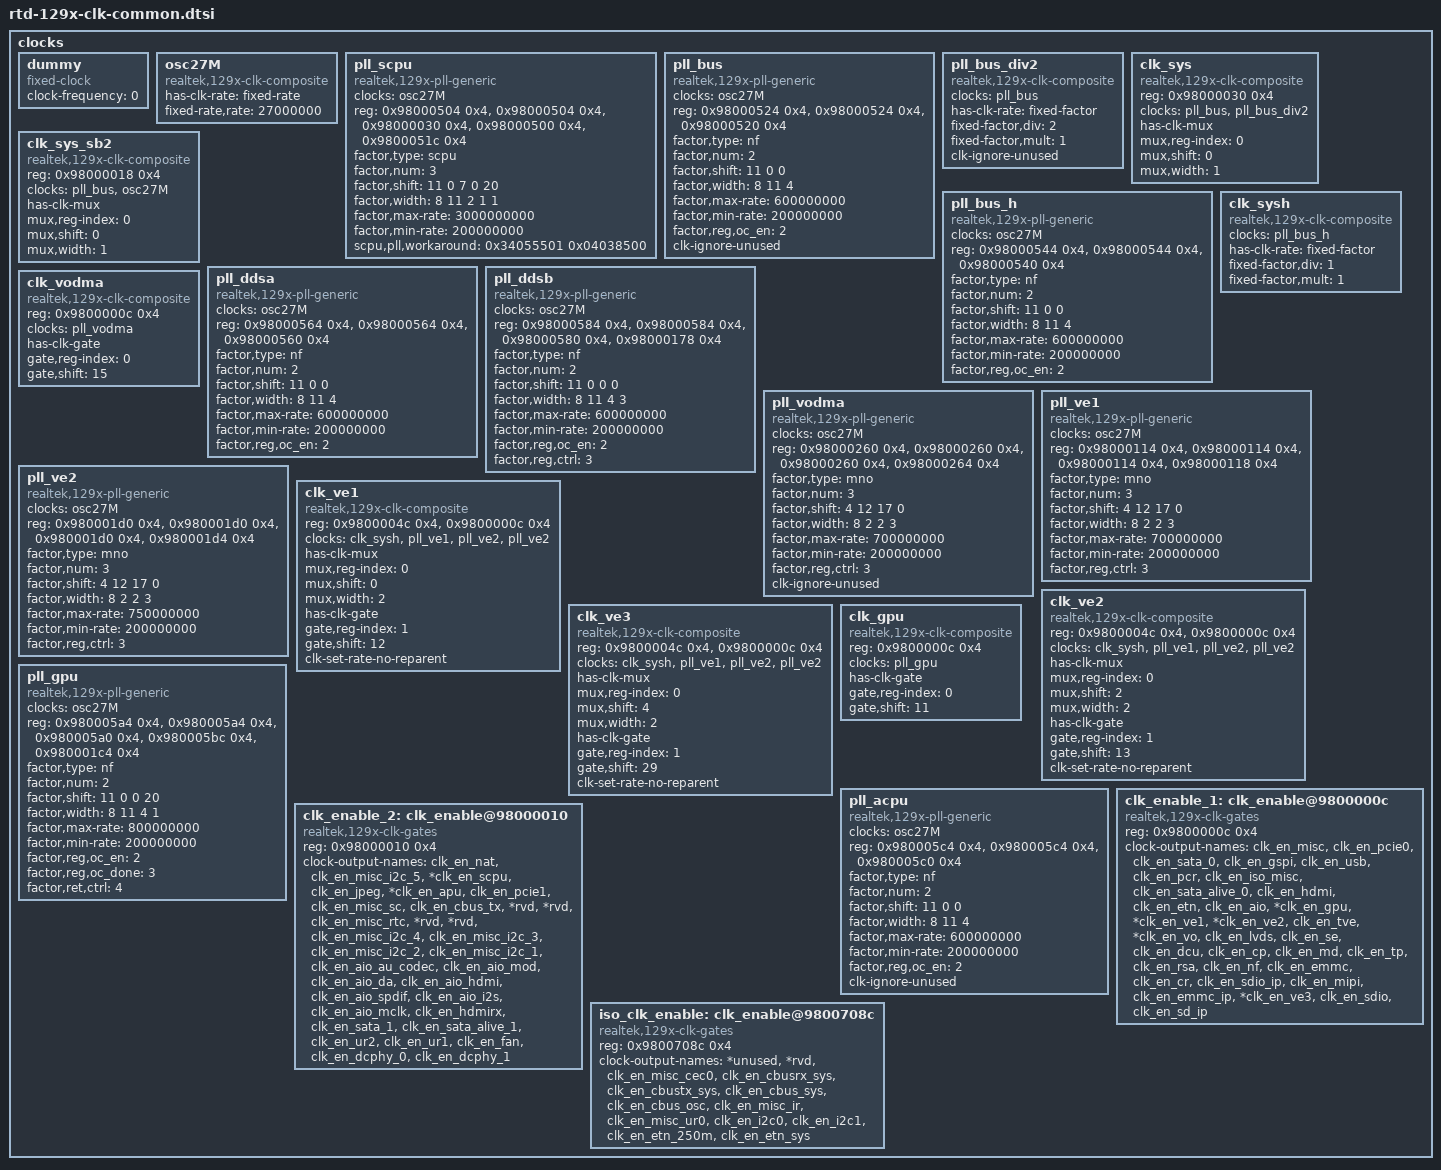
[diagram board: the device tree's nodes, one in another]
/* PLEASE include this file inside a node */
clocks {
    #address-cells = <1>;
    #size-cells = <1>;
    ranges;

    /* This is a dummy clock, to be used as placeholder on
     * other mux clocks when a specific parent clock is not
     * yet implemented. It should be dropped when the driver
     * is complete.
     */
    dummy: dummy {
        compatible = "fixed-clock";
        #clock-cells = <0>;
        clock-frequency = <0>;
    };

    osc27M: osc27M {
        compatible = "realtek,129x-clk-composite";
        #clock-cells = <0>;
        has-clk-rate = "fixed-rate";
        fixed-rate,rate = <27000000>;
    };

    pll_scpu: pll_scpu {
        compatible   = "realtek,129x-pll-generic";
        #clock-cells = <0>;
        clocks       = <&osc27M>;
        reg          = <0x98000504 0x4>,
                       <0x98000504 0x4>,
                       <0x98000030 0x4>,
                       <0x98000500 0x4>, /* oc_en */
                       <0x9800051c 0x4>; /* oc_done */
        factor,type = "scpu";
        factor,num   = <3>;
        factor,shift = <11  0  7  0 20>;
        factor,width = < 8 11  2  1  1>;
        factor,max-rate = <3000000000>;
        factor,min-rate = < 200000000>;            

        scpu,pll,workaround = <
            0x34055501 0x04038500
        >;
    };

    pll_bus: pll_bus {
        compatible   = "realtek,129x-pll-generic";
        #clock-cells = <0>;
        clocks       = <&osc27M>;
        reg          = <0x98000524 0x4>,
                       <0x98000524 0x4>,
                       <0x98000520 0x4>; /* oc_en */
        factor,type  = "nf";
        factor,num   = <2>;
        factor,shift = <11  0 0>;
        factor,width = < 8 11 4>;
        factor,max-rate = <600000000>;
        factor,min-rate = <200000000>;
        factor,reg,oc_en = <2>;

        clk-ignore-unused;
    };

    pll_bus_div2: pll_bus_div2 {
        compatible   = "realtek,129x-clk-composite";
        #clock-cells = <0>;
        clocks       = <&pll_bus>;

        has-clk-rate = "fixed-factor";
        fixed-factor,div  = <2>;
        fixed-factor,mult = <1>;

        clk-ignore-unused;
    };

    clk_sys: clk_sys {
        compatible   = "realtek,129x-clk-composite";
        #clock-cells = <0>;
        reg          = <0x98000030 0x4>;
        clocks       = <&pll_bus>, <&pll_bus_div2>;
        clock-names  = "pll_bus", "pll_bus_div2";

        has-clk-mux;
        mux,reg-index = <0>;
        mux,shift     = <0>;
        mux,width     = <1>;
    };

    clk_sys_sb2 {
        compatible   = "realtek,129x-clk-composite";
        #clock-cells = <0>;
        reg          = <0x98000018 0x4>;
        clocks       = <&pll_bus>, <&osc27M>;
        clock-names  = "pll_bus", "osc27M";
        has-clk-mux;
        mux,reg-index = <0>;
        mux,shift     = <0>;
        mux,width     = <1>;
    };


    pll_bus_h: pll_bus_h {
        compatible   = "realtek,129x-pll-generic";
        #clock-cells = <0>;
        clocks       = <&osc27M>;
        reg          = <0x98000544 0x4>,
                       <0x98000544 0x4>,
                       <0x98000540 0x4>; /* oc_en */
        factor,type  = "nf";
        factor,num   = <2>;
        factor,shift = <11  0 0>;
        factor,width = < 8 11 4>;
        factor,max-rate = <600000000>;
        factor,min-rate = <200000000>;
        factor,reg,oc_en = <2>;
    };

    clk_sysh: clk_sysh {
        compatible   = "realtek,129x-clk-composite";
        #clock-cells = <0>;
        clocks       = <&pll_bus_h>;

        has-clk-rate = "fixed-factor";
        fixed-factor,div  = <1>;
        fixed-factor,mult = <1>;
    };

    pll_ddsa: pll_ddsa {
        compatible   = "realtek,129x-pll-generic";
        #clock-cells = <0>;
        clocks       = <&osc27M>;
        reg          = <0x98000564 0x4>,
                       <0x98000564 0x4>,
                       <0x98000560 0x4>; /* oc_en */
        factor,type  = "nf";
        factor,num   = <2>;
        factor,shift = <11  0 0>;
        factor,width = < 8 11 4>;
        factor,max-rate = <600000000>;
        factor,min-rate = <200000000>;
        factor,reg,oc_en = <2>;
    };

    pll_ddsb: pll_ddsb {
        compatible   = "realtek,129x-pll-generic";
        #clock-cells = <0>;
        clocks       = <&osc27M>;
        reg          = <0x98000584 0x4>,
                       <0x98000584 0x4>,
                       <0x98000580 0x4>, /* oc_en */
                       <0x98000178 0x4>; /* ctrl */
        factor,type  = "nf";
        factor,num   = <2>;
        factor,shift = <11  0 0 0>;
        factor,width = < 8 11 4 3>;
        factor,max-rate = <600000000>;
        factor,min-rate = <200000000>;
        factor,reg,oc_en = <2>;
        factor,reg,ctrl = <3>;
    };

    pll_vodma: pll_vodma {
        compatible   = "realtek,129x-pll-generic";
        #clock-cells = <0>;
        clocks       = <&osc27M>;
        reg          = <0x98000260 0x4>,
                       <0x98000260 0x4>,
                       <0x98000260 0x4>,
                       <0x98000264 0x4>; /* ctrl */
        factor,type  = "mno";
        factor,num   = <3>;
        factor,shift = < 4 12 17 0>;
        factor,width = < 8  2  2 3>;
        factor,max-rate = <700000000>;
        factor,min-rate = <200000000>;
        factor,reg,ctrl = <3>;

        clk-ignore-unused;
    };

    clk_vodma: clk_vodma {
        compatible   = "realtek,129x-clk-composite";
        #clock-cells = <0>;
        reg          = <0x9800000c 0x4>; /* gate */
        clocks       = <&pll_vodma>;

        has-clk-gate;
        gate,reg-index = <0>;
        gate,shift     = <15>;
    };

    pll_ve1: pll_ve1 {
        compatible   = "realtek,129x-pll-generic";
        #clock-cells = <0>;
        clocks       = <&osc27M>;
        reg          = <0x98000114 0x4>,
                       <0x98000114 0x4>,
                       <0x98000114 0x4>, 
                       <0x98000118 0x4>; /* ctrl */
        factor,type  = "mno";
        factor,num   = <3>;
        factor,shift = < 4 12 17 0>;
        factor,width = < 8  2  2 3>;
        factor,max-rate = <700000000>;
        factor,min-rate = <200000000>;
        factor,reg,ctrl = <3>;
    };

    pll_ve2: pll_ve2 {
        compatible   = "realtek,129x-pll-generic";
        #clock-cells = <0>;
        clocks       = <&osc27M>;
        reg          = <0x980001d0 0x4>,
                       <0x980001d0 0x4>,
                       <0x980001d0 0x4>,
                       <0x980001d4 0x4>; /* ctrl */
        factor,type  = "mno";
        factor,num   = <3>;
        factor,shift = < 4 12 17 0>;
        factor,width = < 8  2  2 3>;
        factor,max-rate = <750000000>;
        factor,min-rate = <200000000>;
        factor,reg,ctrl = <3>;
    };

    clk_ve1: clk_ve1 {
        compatible   = "realtek,129x-clk-composite";
        #clock-cells = <0>;
        reg          = <0x9800004c 0x4>, /* mux */
                       <0x9800000c 0x4>; /* gate */
        clocks       = <&clk_sysh>, <&pll_ve1>, <&pll_ve2>, <&pll_ve2>;
        clock-names  = "clk_sysh", "pll_ve1", "pll_ve2", "pll_ve2";

        has-clk-mux;
        mux,reg-index = <0>;
        mux,shift     = <0>;
        mux,width     = <2>;

        has-clk-gate;
        gate,reg-index = <1>;
        gate,shift     = <12>;

        clk-set-rate-no-reparent;
    };

    clk_ve2: clk_ve2 {
        compatible   = "realtek,129x-clk-composite";
        #clock-cells = <0>;
        reg          = <0x9800004c 0x4>, /* mux */
                       <0x9800000c 0x4>; /* gate */
        clocks       = <&clk_sysh>, <&pll_ve1>, <&pll_ve2>, <&pll_ve2>;
        clock-names  = "clk_sysh", "pll_ve1", "pll_ve2", "pll_ve2";

        has-clk-mux;
        mux,reg-index = <0>;
        mux,shift     = <2>;
        mux,width     = <2>;

        has-clk-gate;
        gate,reg-index = <1>;
        gate,shift     = <13>;

        clk-set-rate-no-reparent;
    };

    clk_ve3: clk_ve3 {
        compatible   = "realtek,129x-clk-composite";
        #clock-cells = <0>;
        reg          = <0x9800004c 0x4>, /* mux */
                       <0x9800000c 0x4>; /* gate */
        clocks       = <&clk_sysh>, <&pll_ve1>, <&pll_ve2>, <&pll_ve2>;
        clock-names  = "clk_sysh", "pll_ve1", "pll_ve2", "pll_ve2";

        has-clk-mux;
        mux,reg-index = <0>;
        mux,shift     = <4>;
        mux,width     = <2>;

        has-clk-gate;
        gate,reg-index = <1>;
        gate,shift     = <29>;

        clk-set-rate-no-reparent;
    };

    pll_gpu: pll_gpu {
        compatible   = "realtek,129x-pll-generic";
        #clock-cells = <0>;
        clocks       = <&osc27M>;
        reg          = <0x980005a4 0x4>,
                       <0x980005a4 0x4>,
                       <0x980005a0 0x4>, /* oc_en */
                       <0x980005bc 0x4>, /* oc_done */
                       <0x980001c4 0x4>; /* ctrl */ 
        factor,type = "nf";
        factor,num   = <2>;
        factor,shift = <11  0  0 20>;
        factor,width = < 8 11  4  1>;
        factor,max-rate = <800000000>;
        factor,min-rate = <200000000>;
        factor,reg,oc_en = <2>;
        factor,reg,oc_done = <3>;
        factor,ret,ctrl = <4>;
    };

    clk_gpu: clk_gpu {
        compatible   = "realtek,129x-clk-composite";
        #clock-cells = <0>;
        reg          = <0x9800000c 0x4>; /* gate */
        clocks       = <&pll_gpu>;

        has-clk-gate;
        gate,reg-index = <0>;
        gate,shift     = <11>;
    };

    pll_acpu: pll_acpu {
        compatible   = "realtek,129x-pll-generic";
        #clock-cells = <0>;
        clocks       = <&osc27M>;
        reg          = <0x980005c4 0x4>,
                       <0x980005c4 0x4>,
                       <0x980005c0 0x4>; /* oc_en */
        factor,type  = "nf";
        factor,num   = <2>;
        factor,shift = <11  0 0>;
        factor,width = < 8 11 4>;
        factor,max-rate = <600000000>;
        factor,min-rate = <200000000>;
        factor,reg,oc_en = <2>;

        clk-ignore-unused;
    };

    clk_enable_1: clk_enable@9800000c {
        compatible   = "realtek,129x-clk-gates";
        #clock-cells = <1>;
        reg          = <0x9800000c 0x4>;           
        clock-output-names =
            "clk_en_misc",    "clk_en_pcie0", "clk_en_sata_0",   "clk_en_gspi",
            "clk_en_usb",     "clk_en_pcr",   "clk_en_iso_misc", "clk_en_sata_alive_0",
            "clk_en_hdmi",    "clk_en_etn",   "clk_en_aio",      "*clk_en_gpu",
            "*clk_en_ve1",    "*clk_en_ve2",  "clk_en_tve",      "*clk_en_vo",
            "clk_en_lvds",    "clk_en_se",    "clk_en_dcu",      "clk_en_cp",
            "clk_en_md",      "clk_en_tp",    "clk_en_rsa",      "clk_en_nf",
            "clk_en_emmc",    "clk_en_cr",    "clk_en_sdio_ip",  "clk_en_mipi",
            "clk_en_emmc_ip", "*clk_en_ve3",  "clk_en_sdio",     "clk_en_sd_ip";
    };

    clk_enable_2: clk_enable@98000010 {
        compatible   = "realtek,129x-clk-gates";
        #clock-cells = <1>;
        reg          = <0x98000010 0x4>;

        clock-output-names =
            "clk_en_nat",        "clk_en_misc_i2c_5",   "*clk_en_scpu",        "clk_en_jpeg",
            "*clk_en_apu",       "clk_en_pcie1",        "clk_en_misc_sc",      "clk_en_cbus_tx",
            "*rvd",              "*rvd",                "clk_en_misc_rtc",     "*rvd",
            "*rvd",              "clk_en_misc_i2c_4",   "clk_en_misc_i2c_3",   "clk_en_misc_i2c_2",
            "clk_en_misc_i2c_1", "clk_en_aio_au_codec", "clk_en_aio_mod",      "clk_en_aio_da",
            "clk_en_aio_hdmi",   "clk_en_aio_spdif",    "clk_en_aio_i2s",      "clk_en_aio_mclk",
            "clk_en_hdmirx",     "clk_en_sata_1",       "clk_en_sata_alive_1", "clk_en_ur2",
            "clk_en_ur1",        "clk_en_fan",          "clk_en_dcphy_0",      "clk_en_dcphy_1";
    };

    iso_clk_enable: clk_enable@9800708c {
        compatible   = "realtek,129x-clk-gates";
        #clock-cells = <1>;
        reg          = <0x9800708c 0x4>;
        clock-output-names = 
            "*unused",           "*rvd",            "clk_en_misc_cec0", "clk_en_cbusrx_sys",
            "clk_en_cbustx_sys", "clk_en_cbus_sys", "clk_en_cbus_osc",  "clk_en_misc_ir",
            "clk_en_misc_ur0",   "clk_en_i2c0",     "clk_en_i2c1",      "clk_en_etn_250m",
            "clk_en_etn_sys";
    };
};
